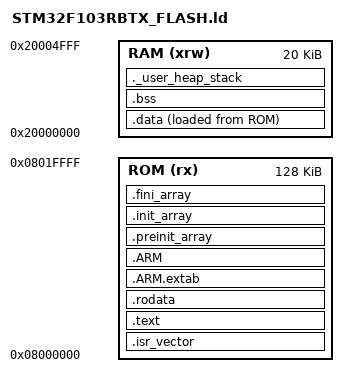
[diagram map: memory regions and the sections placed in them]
/* Linker script for STM32F103RB (NUCLEO-F103RB): 128 KB flash, 20 KB RAM. */

ENTRY(Reset_Handler)

_estack = ORIGIN(RAM) + LENGTH(RAM);

_Min_Heap_Size = 0x400;  /* newlib malloc (RAM file store) */
_Min_Stack_Size = 0x300; /* main() and interrupts before the scheduler */

MEMORY
{
  RAM    (xrw)   : ORIGIN = 0x20000000,   LENGTH = 20K
  ROM    (rx)    : ORIGIN = 0x08000000,   LENGTH = 128K
}

SECTIONS
{
  .isr_vector :
  {
    . = ALIGN(4);
    KEEP(*(.isr_vector))
    . = ALIGN(4);
  } >ROM

  .text :
  {
    . = ALIGN(4);
    *(.text)
    *(.text*)
    *(.glue_7)
    *(.glue_7t)
    *(.eh_frame)

    KEEP (*(.init))
    KEEP (*(.fini))

    . = ALIGN(4);
    _etext = .;
  } >ROM

  .rodata :
  {
    . = ALIGN(4);
    *(.rodata)
    *(.rodata*)
    . = ALIGN(4);
  } >ROM

  .ARM.extab :
  {
    *(.ARM.extab* .gnu.linkonce.armextab.*)
  } >ROM

  .ARM :
  {
    __exidx_start = .;
    *(.ARM.exidx*)
    __exidx_end = .;
  } >ROM

  .preinit_array :
  {
    PROVIDE_HIDDEN (__preinit_array_start = .);
    KEEP (*(.preinit_array*))
    PROVIDE_HIDDEN (__preinit_array_end = .);
  } >ROM

  .init_array :
  {
    PROVIDE_HIDDEN (__init_array_start = .);
    KEEP (*(SORT(.init_array.*)))
    KEEP (*(.init_array*))
    PROVIDE_HIDDEN (__init_array_end = .);
  } >ROM

  .fini_array :
  {
    PROVIDE_HIDDEN (__fini_array_start = .);
    KEEP (*(SORT(.fini_array.*)))
    KEEP (*(.fini_array*))
    PROVIDE_HIDDEN (__fini_array_end = .);
  } >ROM

  _sidata = LOADADDR(.data);

  .data :
  {
    . = ALIGN(4);
    _sdata = .;
    *(.data)
    *(.data*)
    *(.RamFunc)
    *(.RamFunc*)
    . = ALIGN(4);
    _edata = .;
  } >RAM AT> ROM

  . = ALIGN(4);
  .bss :
  {
    _sbss = .;
    __bss_start__ = _sbss;
    *(.bss)
    *(.bss*)
    *(COMMON)
    . = ALIGN(4);
    _ebss = .;
    __bss_end__ = _ebss;
  } >RAM

  ._user_heap_stack :
  {
    . = ALIGN(8);
    PROVIDE ( end = . );
    PROVIDE ( _end = . );
    . = . + _Min_Heap_Size;
    . = . + _Min_Stack_Size;
    . = ALIGN(8);
  } >RAM

  /DISCARD/ :
  {
    libc.a ( * )
    libm.a ( * )
    libgcc.a ( * )
  }

  .ARM.attributes 0 : { *(.ARM.attributes) }
}
